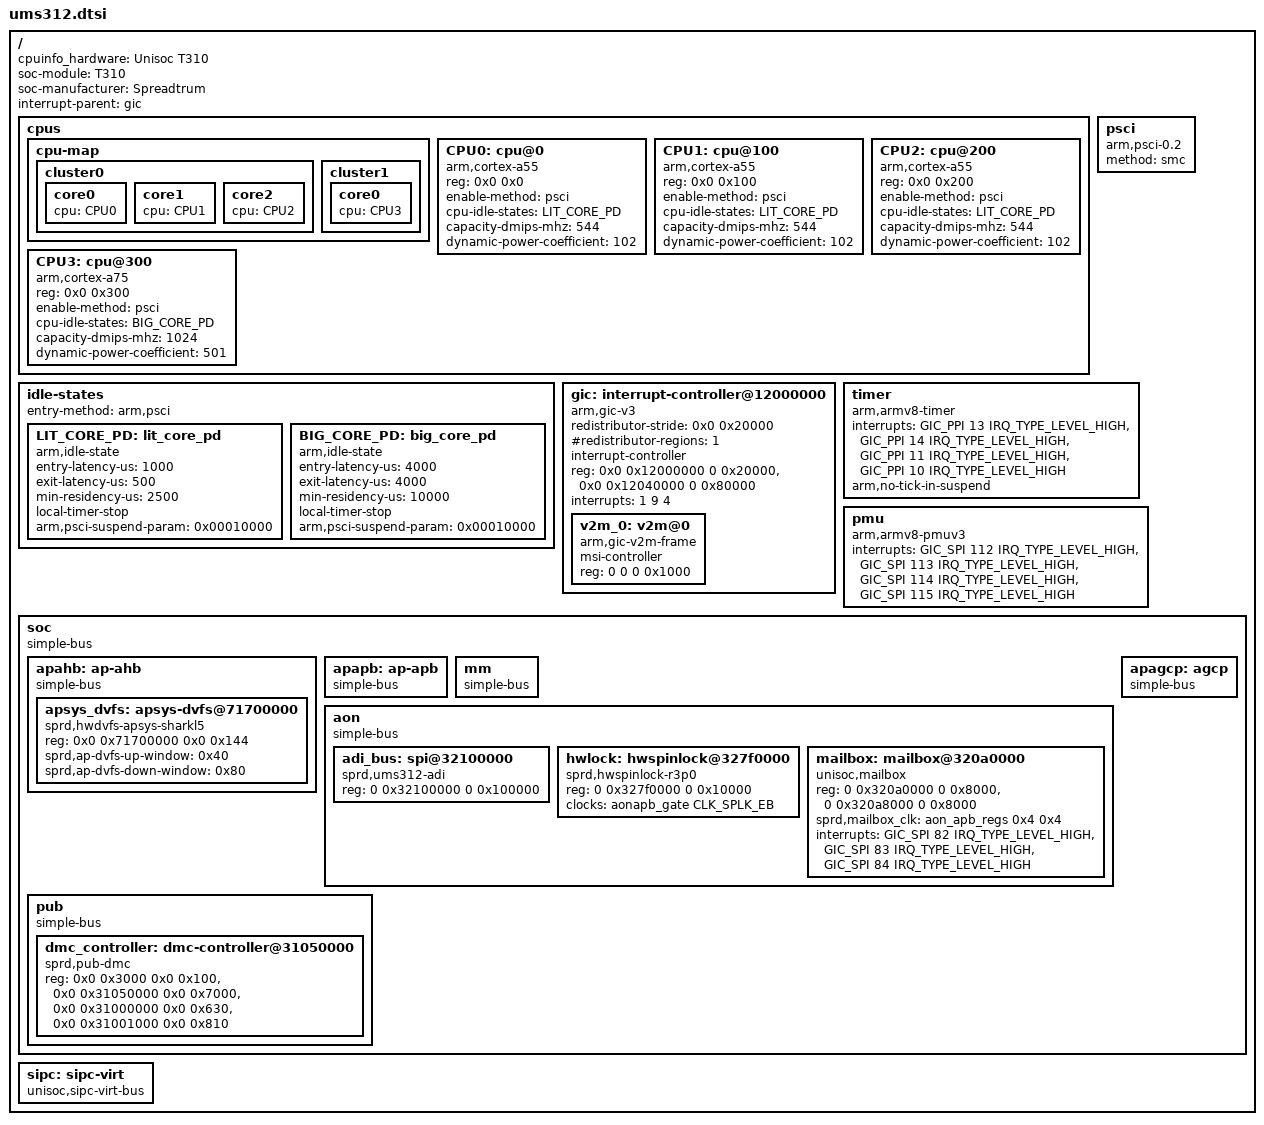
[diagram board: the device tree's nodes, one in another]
// SPDX-License-Identifier: (GPL-2.0+ OR MIT)
/*
 * UNISOC UMS312 platform DTS file
 *
 * Copyright (C) 2018, Spreadtrum Communications Inc.
 */

#include <dt-bindings/interrupt-controller/arm-gic.h>
#include <dt-bindings/clock/sprd,ums312-clk.h>
#include <dt-bindings/reset/sprd,ums312-reset.h>

/ {
	cpuinfo_hardware = "Unisoc T310";
	soc-module = "T310";
	soc-manufacturer = "Spreadtrum";
	interrupt-parent = <&gic>;
	#address-cells = <2>;
	#size-cells = <2>;

	cpus {
		#address-cells = <2>;
		#size-cells = <0>;

		cpu-map {
			cluster0 {
				core0 {
					cpu = <&CPU0>;
				};
				core1 {
					cpu = <&CPU1>;
				};
				core2 {
					cpu = <&CPU2>;
				};
			};
			cluster1 {
				core0 {
					cpu = <&CPU3>;
				};
			};
		};

		CPU0: cpu@0 {
			device_type = "cpu";
			compatible = "arm,cortex-a55","arm,armv8";
			reg = <0x0 0x0>;
			enable-method = "psci";
			cpu-idle-states = <&LIT_CORE_PD>;
			capacity-dmips-mhz = <544>;
			dynamic-power-coefficient = <102>;
			#cooling-cells = <2>;
		};
		CPU1: cpu@100 {
			device_type = "cpu";
			compatible = "arm,cortex-a55","arm,armv8";
			reg = <0x0 0x100>;
			enable-method = "psci";
			cpu-idle-states = <&LIT_CORE_PD>;
			capacity-dmips-mhz = <544>;
			dynamic-power-coefficient = <102>;
			#cooling-cells = <2>;
		};
		CPU2: cpu@200 {
			device_type = "cpu";
			compatible = "arm,cortex-a55","arm,armv8";
			reg = <0x0 0x200>;
			enable-method = "psci";
			cpu-idle-states = <&LIT_CORE_PD>;
			capacity-dmips-mhz = <544>;
			dynamic-power-coefficient = <102>;
			#cooling-cells = <2>;
		};
		CPU3: cpu@300 {
			device_type = "cpu";
			compatible = "arm,cortex-a75","arm,armv8";
			reg = <0x0 0x300>;
			enable-method = "psci";
			cpu-idle-states = <&BIG_CORE_PD>;
			capacity-dmips-mhz = <1024>;
			dynamic-power-coefficient = <501>;
			#cooling-cells = <2>;
		};
	};

	psci {
		compatible = "arm,psci-0.2";
		method = "smc";
	};

	idle-states {
		entry-method = "arm,psci";
		LIT_CORE_PD: lit_core_pd {
			compatible = "arm,idle-state";
			entry-latency-us = <1000>;
			exit-latency-us = <500>;
			min-residency-us = <2500>;
			local-timer-stop;
			arm,psci-suspend-param = <0x00010000>;
		};
		BIG_CORE_PD: big_core_pd {
			compatible = "arm,idle-state";
			entry-latency-us = <4000>;
			exit-latency-us = <4000>;
			min-residency-us = <10000>;
			local-timer-stop;
			arm,psci-suspend-param = <0x00010000>;
		};
	};


	gic: interrupt-controller@12000000 {
		compatible = "arm,gic-v3";
		#interrupt-cells = <3>;
		#address-cells = <2>;
		#size-cells = <2>;
		ranges;
		redistributor-stride = <0x0 0x20000>;	/* 128KB stride */
		#redistributor-regions = <1>;
		interrupt-controller;
		reg = <0x0 0x12000000 0 0x20000>,	/* GICD */
			<0x0 0x12040000 0 0x80000>;	/* GICR */
		interrupts = <1 9 4>;
		v2m_0: v2m@0 {
			compatible = "arm,gic-v2m-frame";
			msi-controller;
			reg = <0 0 0 0x1000>;
		};
	};

	timer {
		compatible = "arm,armv8-timer";
		interrupts = <GIC_PPI 13 IRQ_TYPE_LEVEL_HIGH>, /* Physical Secure PPI */
			<GIC_PPI 14 IRQ_TYPE_LEVEL_HIGH>, /* Physical Non-Secure PPI */
			<GIC_PPI 11 IRQ_TYPE_LEVEL_HIGH>, /* Virtual PPI */
			<GIC_PPI 10 IRQ_TYPE_LEVEL_HIGH>; /* Hipervisor PPI */
		arm,no-tick-in-suspend;
	};

	pmu {
		compatible = "arm,armv8-pmuv3";
		interrupts = <GIC_SPI 112 IRQ_TYPE_LEVEL_HIGH>,
				<GIC_SPI 113 IRQ_TYPE_LEVEL_HIGH>,
				<GIC_SPI 114 IRQ_TYPE_LEVEL_HIGH>,
				<GIC_SPI 115 IRQ_TYPE_LEVEL_HIGH>;
	};

	soc: soc {
		compatible = "simple-bus";
		#address-cells = <2>;
		#size-cells = <2>;
		ranges;

		apahb: ap-ahb {
			compatible = "simple-bus";
			#address-cells = <2>;
			#size-cells = <2>;
			ranges;

			apsys_dvfs: apsys-dvfs@71700000 {
				compatible = "sprd,hwdvfs-apsys-sharkl5";
				reg = <0x0 0x71700000 0x0 0x144>;

				sprd,ap-dvfs-up-window = <0x40>;
				sprd,ap-dvfs-down-window = <0x80>;
			};
		};

		apapb: ap-apb {
			compatible = "simple-bus";
			#address-cells = <2>;
			#size-cells = <2>;
			ranges;
		};

		mm: mm {
			compatible = "simple-bus";
			#address-cells = <2>;
			#size-cells = <2>;
			ranges;
		};

		aon: aon {
			compatible = "simple-bus";
			#address-cells = <2>;
			#size-cells = <2>;
			ranges;

			adi_bus: spi@32100000 {
				compatible = "sprd,ums312-adi",
						"sprd,ums512-adi";
				reg = <0 0x32100000 0 0x100000>;
				#address-cells = <1>;
				#size-cells = <0>;
			};

			hwlock: hwspinlock@327f0000 {
				compatible = "sprd,hwspinlock-r3p0";
				reg = <0 0x327f0000 0 0x10000>;
				#hwlock-cells = <1>;
				clock-names = "enable";
				clocks = <&aonapb_gate CLK_SPLK_EB>;
			};

			mailbox: mailbox@320a0000 {
				compatible = "unisoc,mailbox";
				reg = <0 0x320a0000 0 0x8000>,
				      <0 0x320a8000 0 0x8000>;
				reg-names = "inbox", "outbox";
				sprd,mailbox_clk = <&aon_apb_regs 0x4 0x4>;
				interrupts = <GIC_SPI 82 IRQ_TYPE_LEVEL_HIGH>,
					     <GIC_SPI 83 IRQ_TYPE_LEVEL_HIGH>,
					     <GIC_SPI 84 IRQ_TYPE_LEVEL_HIGH>;
				interrupt-names = "inbox", "outbox", "oob-outbox";
				#mbox-cells = <2>;
			};
		};

		apagcp: agcp {
			compatible = "simple-bus";
			#address-cells = <2>;
			#size-cells = <2>;
			ranges;
		};

		pub: pub {
			compatible = "simple-bus";
			#address-cells = <2>;
			#size-cells = <2>;
			ranges;

			dmc_controller: dmc-controller@31050000 {
				compatible = "sprd,pub-dmc";
				reg = <0x0 0x3000 0x0 0x100>, /* proc_res */
					<0x0 0x31050000 0x0 0x7000>, /* mon_res */
					<0x0 0x31000000 0x0 0x630>, /* dmc_res */
					<0x0 0x31001000 0x0 0x810>; /* phy0/1_res */
			};
		};
	};

	sipc: sipc-virt {
		compatible = "unisoc,sipc-virt-bus";
		#address-cells = <1>;
		#size-cells = <0>;
	};
};


/* Include other IP modules in ALPHABETICAL order */
#include "apcpu-dvfs.dtsi"
#include "ddr-dfs.dtsi"
#include "bm.dtsi"
#include "dma.dtsi"
#include "dmc-mpu.dtsi"
#include "efuse.dtsi"
#include "glbreg.dtsi"
#include "cam.dtsi"
#include "csi.dtsi"
#include "gpio.dtsi"
#include "i2c.dtsi"
#include "mipi-serdes.dtsi"
#include "pinctrl.dtsi"
#include "power.dtsi"
#include "ptm.dtsi"
#include "pnp.dtsi"
#include "pwm.dtsi"
#include "sdio.dtsi"
#include "sensorhub.dtsi"
#include "socid.dtsi"
#include "spi.dtsi"
#include "timer.dtsi"
#include "uart.dtsi"
#include "usb.dtsi"
#include "wdt.dtsi"
#include "dispc.dtsi"
#include "gpu.dtsi"
#include "modem.dtsi"
#include "audio.dtsi"
#include "i2s.dtsi"
#include "thermal.dtsi"
#include "vsp.dtsi"
#include "qos.dtsi"
#include "coresight.dtsi"
#include "jpg.dtsi"
